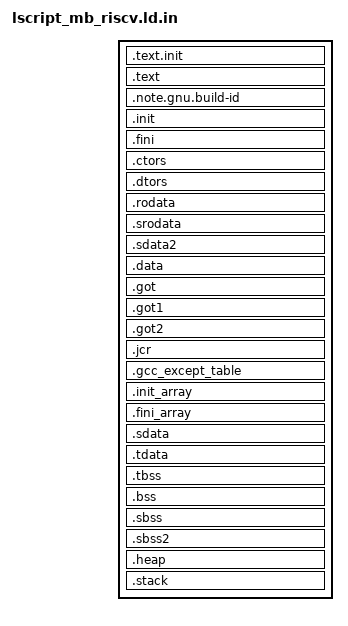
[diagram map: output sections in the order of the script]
/******************************************************************************
* Copyright (C) 2023 Advanced Micro Devices, Inc. All Rights Reserved.
* SPDX-License-Identifier: MIT
******************************************************************************/

_STACK_SIZE = DEFINED(_STACK_SIZE) ? _STACK_SIZE : @STACK_SIZE@;
_HEAP_SIZE = DEFINED(_HEAP_SIZE) ? _HEAP_SIZE : @HEAP_SIZE@;

/* Define Memories in the system */

@MEMORY_SECTION@

/* Specify the default entry point to the program */

ENTRY(_boot)

/* Define the sections, and where they are mapped in memory */

SECTIONS
{
.text.init : {
   __text.init_start = .;
   *(.text.init)
   __text.init_end = .;
} > @DDR@

.text : {
   . = ALIGN(2048);
   *(.text)
   *(.text.*)
   *(.gnu.linkonce.t.*)
} > @DDR@

.note.gnu.build-id : {
   KEEP (*(.note.gnu.build-id))
} > @DDR@

.init : {
   KEEP (*(.init))
} > @DDR@

.fini : {
   KEEP (*(.fini))
} > @DDR@

.ctors : {
   __CTOR_LIST__ = .;
   ___CTORS_LIST___ = .;
   KEEP (*crtbegin.o(.ctors))
   KEEP (*(EXCLUDE_FILE(*crtend.o) .ctors))
   KEEP (*(SORT(.ctors.*)))
   KEEP (*(.ctors))
   __CTOR_END__ = .;
   ___CTORS_END___ = .;
} > @DDR@

.dtors : {
   __DTOR_LIST__ = .;
   ___DTORS_LIST___ = .;
   KEEP (*crtbegin.o(.dtors))
   KEEP (*(EXCLUDE_FILE(*crtend.o) .dtors))
   KEEP (*(SORT(.dtors.*)))
   KEEP (*(.dtors))
   __DTOR_END__ = .;
   ___DTORS_END___ = .;
} > @DDR@

.rodata : {
   __rodata_start = .;
   *(.rodata)
   *(.rodata.*)
   *(.gnu.linkonce.r.*)
   __rodata_end = .;
} > @DDR@

.srodata : {
   __srodata_start = .;
   *(.srodata)
   __srodata_end = .;
} > @DDR@

.sdata2 : {
   __sdata2_start = .;
   *(.sdata2)
   *(.sdata2.*)
   *(.gnu.linkonce.s2.*)
   __sdata2_end = .;
} > @DDR@

.data : {
   __data_start = .;
   *(.data)
   *(.data.*)
   *(.gnu.linkonce.d.*)
   _edata = .;
} > @DDR@

.got : {
   *(.got)
} > @DDR@

.got1 : {
   *(.got1)
} > @DDR@

.got2 : {
   *(.got2)
} > @DDR@

.jcr : {
   *(.jcr)
} > @DDR@

.gcc_except_table : {
   *(.gcc_except_table)
} > @DDR@

.init_array : {
   __init_array_start = .;
   KEEP (*(SORT(.init_array.*)))
   KEEP (*(.init_array))
   __init_array_end = .;
} > @DDR@

.fini_array : {
   __fini_array_start = .;
   KEEP (*(SORT(.fini_array.*)))
   KEEP (*(.fini_array))
   __fini_array_end = .;
} > @DDR@

.sdata : {
   __sdata_start = .;
   *(.sdata)
   *(.sdata.*)
   *(.gnu.linkonce.s.*)
   __sdata_end = .;
} > @DDR@

.tdata : {
   __tdata_start = .;
   *(.tdata)
   *(.tdata.*)
   *(.gnu.linkonce.td.*)
   __tdata_end = .;
} > @DDR@

.tbss : {
   __tbss_start = .;
   *(.tbss)
   *(.tbss.*)
   *(.gnu.linkonce.tb.*)
   __tbss_end = .;
} > @DDR@

.bss (NOLOAD) : {
   __bss_start = .;
   *(.bss)
   *(.bss.*)
   *(.gnu.linkonce.b.*)
   *(COMMON)
   __bss_end = .;
} > @DDR@

.sbss (NOLOAD) : {
   __sbss_start = .;
   *(.sbss)
   *(.sbss.*)
   *(.gnu.linkonce.sb.*)
   __sbss_end = .;
} > @DDR@

.sbss2 : {
   __sbss2_start = .;
   *(.sbss2)
   *(.sbss2.*)
   *(.gnu.linkonce.sb2.*)
   __sbss2_end = .;
} > @DDR@

_SDA_BASE_ = __sdata_start + ((__sbss_end - __sdata_start) / 2 );

_SDA2_BASE_ = __sdata2_start + ((__sbss2_end - __sdata2_start) / 2 );

/* Generate Stack and Heap definitions */

.heap (NOLOAD) : {
   . = ALIGN(8);
   _heap = .;
   _heap_start = .;
   . += _HEAP_SIZE;
   _heap_end = .;
} > @DDR@

.stack (NOLOAD) : {
   _stack_end = .;
   . += _STACK_SIZE;
   . = ALIGN(8);
   _stack = .;
   __stack = _stack;
} > @DDR@

__global_pointer$ = MIN(__sdata_start + 0x800, MAX(__data_start + 0x800, __bss_end - 0x800));
_end = .;
}
